# S6E1C1xD register map
Vendor: Cypress; File version: 2.0
S6E1C1 Series package D
CPU: CM0PLUS r0p1, little endian, no MPU, no FPU, 2 interrupt priority bits
Registers are 32-bit, read-write, reset 0x0 unless marked. A register's access mark holds for its fields unless they carry their own. Offsets are from the block's base; lines under a group give offsets from that group; [hi:lo] are bit positions; {n}, {i} and the like mark numbered series; 'fields as' and 'values as' point back to an identical list; <NAME> marks a mode.

## Memory map
0x40000000 FLASH_IF blocks up to offset 0x104 — Flash Memory
0x40000200 UNIQUE_ID blocks up to offset 0x8
0x40010000 CRG blocks up to offset 0x6C — Clock Unit Registers
0x40011000 HWWDT blocks up to offset 0xC04 — Hardware Watchdog Timer
0x40012000 SWWDT blocks up to offset 0xC04 — Software Watchdog Timer
0x40015000 DT blocks up to offset 0x3C — Dual Timer
0x40025000 BT0 blocks up to offset 0x12 — Base Timer 0
0x40025040 BT1 blocks up to offset 0x12 — Base Timer 1
0x40025080 BT2 blocks up to offset 0x12 — Base Timer 2
0x400250C0 BT3 blocks up to offset 0x12 — Base Timer 3
0x40025100 BTIOSEL03 size 0x2 — Base Timer I/O Select
0x40025200 BT4 blocks up to offset 0x12 — Base Timer 4
0x40025240 BT5 blocks up to offset 0x12 — Base Timer 5
0x40025280 BT6 blocks up to offset 0x12 — Base Timer 6
0x400252C0 BT7 blocks up to offset 0x12 — Base Timer 7
0x40025300 BTIOSEL47 blocks up to offset 0x2 — Base Timer I/O Select
0x40025F00 SBSSR blocks up to offset 0xFE — Software-based Simultaneous Startup Register
0x40027000 ADC0 blocks up to offset 0x54 — ADC0 Registers
0x4002E000 CRTRIM blocks up to offset 0x10 — CR Trimming Registers
0x40030000 EXTI blocks up to offset 0x21 — External Interrupt and NMI Control
0x40031000 INTREQ blocks up to offset 0x284 — Interrupts
0x40033000 GPIO blocks up to offset 0x940 — I/O Port Registers
0x40034000 HDMICEC0 blocks up to offset 0x66 — HDMI-CEC ch.0
0x40034100 HDMICEC1 blocks up to offset 0x66 — HDMI-CEC ch.1
0x40035000 LVD blocks up to offset 0x1E — Low-voltage Detection
0x40035100 DS blocks up to offset 0x90D — Low Power Consumption Mode Registers
0x40037980 I2CSLAVE blocks up to offset 0x16 — I2C Slave Wakeup
0x40038000 MFS0 blocks up to offset 0x42 — Multi-function Serial Interface 0
0x40038100 MFS1 blocks up to offset 0x42 — Multi-function Serial Interface 1
0x40038300 MFS3 blocks up to offset 0x42 — Multi-function Serial Interface 3
0x40038400 MFS4 blocks up to offset 0x42 — Multi-function Serial Interface 4
0x40038600 MFS6 blocks up to offset 0x42 — Multi-function Serial Interface 6
0x40038700 MFS7 blocks up to offset 0x42 — Multi-function Serial Interface 7
0x40039000 CRC blocks up to offset 0x10 — CRC Registers
0x4003A000 WC blocks up to offset 0x15 — Watch Counter
0x4003B000 RTC blocks up to offset 0x31 — REAL-TIME CLOCK
0x4003C000 LSCRP size 0x1 — Low-speed CR Prescaler Register
0x4003C100 CLK_GATING blocks up to offset 0x28 — Peripheral Clock Gating Registers
0x4003C980 SMCIF1 blocks up to offset 0x42 — Smart Card Interface 1 Registers
0x4003CA00 MFSI2S0 blocks up to offset 0xA — I2S0 Registers
0x4003CA80 MFSI2S1 blocks up to offset 0xA — I2S1 Registers
0x40061000 DSTC blocks up to offset 0x98 — DSTC registers
0xF0001000 MTB_DWT blocks up to offset 0x1000 — Micro Trace Buffer Data Watchpoint and Trace Registers
0xF8000000 FASTIO size 0x100 — Fast GPIO Registers
0xF8000100 VIR size 0x80 — Vector Indicate Registers

## Interrupts
0 CSV_SWDT_LVD (CRG, SWWDT, LVD)
1 FMS0_RX_TX (MFS0)
2 FMS1_RX_TX (MFS1)
4 FMS3_RX_TX (MFS3)
8 FMS7_RX_TX (MFS7)
9 ADC0
14 TIM (CRG)
15 WC_RTC_DT (DT, WC, RTC)
16 EXINT0_1 (EXTI)
17 EXINT2_3 (EXTI)
18 EXINT4_5 (EXTI)
19 EXINT6_7 (EXTI)
20 EXINT8 (EXTI)
22 EXINT12_13 (EXTI)
23 EXINT15 (EXTI)
24 BT0_4 (BT0, BT4)
25 BT1_5 (BT1, BT5)
26 BT2_6 (BT2, BT6)
27 BT3_7 (BT3, BT7)
28 HDMICEC0_1 (HDMICEC0, HDMICEC1)
29 SMCIF1_FLASHIF (FLASH_IF, SMCIF1)
30 DSTC

## Further device data
mcutype=3

## FLASH_IF — Flash Memory
Base 0x40000000
0x04 FRWTR 8-bit reset 0x3 — Flash Read Wait Register
  [1:0] RWT — Read Wait Cycle
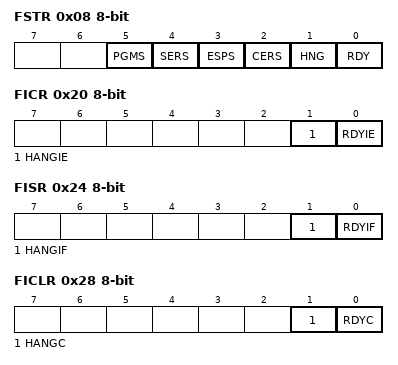
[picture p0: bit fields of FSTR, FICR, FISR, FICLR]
0x08 FSTR 8-bit ro — Flash Status Register
  [5] PGMS — Flash Program Status
  [4] SERS — Flash Sector Erase Status
  [3] ESPS — Flash Erase Suspend Status
  [2] CERS — Flash Chip Erase Status
  [1] HNG — Flash Hang Status
  [0] RDY — Flash Ready Status
0x10 FSYNDN 8-bit reset 0x1 — Flash Sync Down Register
  [3:0] SD — Sync Down
0x20 FICR 8-bit — Flash Interrupt Control Register
  [1] HANGIE — HANG Interrupt Enable
  [0] RDYIE — RDY Interrupt Enable
0x24 FISR 8-bit — Flash Interrupt Status Register
  [1] HANGIF — HANG Interrupt Flag
  [0] RDYIF — RDY Interrupt Flag
0x28 FICLR 8-bit wo — Flash Interrupt Clear Register
  [1] HANGC — HANG Interrupt Clear
  [0] RDYC — RDY Interrupt Clear
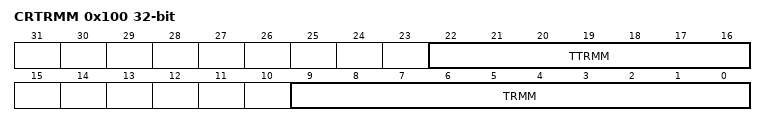
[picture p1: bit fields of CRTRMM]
0x100 CRTRMM ro — CR Trimming Data Mirror Register
  [22:16] TTRMM — CR Temperature Trimming Data Mirror Bit
  [9:0] TRMM — CR Trimming Data Mirror Bit

## Notices in the file
Copyright (C) 2013-2015, Cypress Semiconductor Corporation. All Rights Reserved.
This software, including source code, documentation and related
materials ( "Software" ), is owned by Cypress Semiconductor
Corporation ( "Cypress" ) and is protected by and subject to worldwide
patent protection (United States and foreign), United States copyright
laws and international treaty provisions. Therefore, you may use this
Software only as provided in the license agreement accompanying the
software package from which you obtained this Software ( "EULA" ).
If no EULA applies, Cypress hereby grants you a personal, nonexclusive,
non-transferable license to copy, modify, and compile the
Software source code solely for use in connection with Cypress's
integrated circuit products. Any reproduction, modification, translation,
compilation, or representation of this Software except as specified
above is prohibited without the express written permission of Cypress.
Disclaimer: THIS SOFTWARE IS PROVIDED AS-IS, WITH NO
WARRANTY OF ANY KIND, EXPRESS OR IMPLIED, INCLUDING,
BUT NOT LIMITED TO, NONINFRINGEMENT, IMPLIED
WARRANTIES OF MERCHANTABILITY AND FITNESS FOR A
PARTICULAR PURPOSE. Cypress reserves the right to make
changes to the Software without notice. Cypress does not assume any
liability arising out of the application or use of the Software or any
product or circuit described in the Software. Cypress does not
authorize its products for use in any products where a malfunction or
failure of the Cypress product may reasonably be expected to result in
significant property damage, injury or death ( "High Risk Product" ). By
including Cypress's product in a High Risk Product, the manufacturer
of such system or application assumes all risk of such use and in doing
so agrees to indemnify Cypress against all liability.
